# core register map
Vendor: litex
Registers are 32-bit, read-write, reset 0x0 unless marked. A register's access mark holds for its fields unless they carry their own. Offsets are from the block's base; [hi:lo] are bit positions; {n}, {i} and the like mark numbered series.

## COREUSER
Base 0xE0002000
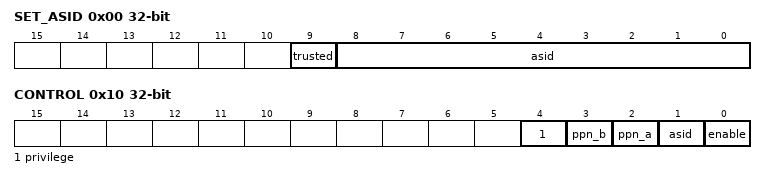
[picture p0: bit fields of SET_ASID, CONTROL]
0x00 SET_ASID
  [9] trusted — Set to `1` if the ASID is trusted
  [8:0] asid — ASID to set. Writing to this register commits the value in `trusted` to the specified `asid` value
0x04 GET_ASID_ADDR
  [8:0] asid — ASID to read back.
0x08 GET_ASID_VALUE
  [0] value — Value corresponding to the ASID specified in `get_asid_addr`. `1` means trusted
0x0C SET_PRIVILEGE
  [1:0] mpp — Value of `mpp` bit from `mstatus` that must match for code to be trusted
0x10 CONTROL
  [4] privilege — When set to `1`, requires the current privilege state to match that specified in `set_privilege.mpp`
  [3] ppn_b — When set to `1`, requires the `b` `ppn` window to be trusted to assert `CoreUser`
  [2] ppn_a — When set to `1`, requires the `a` `ppn` window to be trusted to assert `CoreUser`
  [1] asid — When `1`, requires the ASID mapping to be trusted to assert `CoreUser`
  [0] enable — Enable `CoreUser` computation. When set to `1`, the settings are applied; when cleared to `0`, the `CoreUser` signal is always valid. Defaults to `0`.
0x14 PROTECT — Writing `1` to this bit prevents any further updates to CoreUser configuration status. Can only be reversed with a system reset.
  [0] protect
0x18 WINDOW_AL
  [21:0] ppn — PPN match value, `a` window lower bound. Matches if ppn is greater than or equal to this value
0x1C WINDOW_AH
  [21:0] ppn — PPN match value, `a` window upper bound. Matches if ppn is less than or equal to this value (so a value of 255 would match everything from 0 to 255; resulting in 256 total locations
0x20 WINDOW_BL
  [21:0] ppn — PPN match value, `b` window lower bound. Matches if ppn is greater than or equal to this value
0x24 WINDOW_BH
  [21:0] ppn — PPN match value, `b` window upper bound. Matches if ppn is less than or equal to this value (so a value of 255 would match everything from 0 to 255; resulting in 256 total locations

## CSRTEST
Base 0xE0003000
0x00 WTEST — Write test data here
0x04 RTEST — Read test data here

## IRQARRAY0
Base 0xE0004000
Same registers: IRQARRAY1 0xE0005000, IRQARRAY{n} {0xDFFFC000+0x1000*n} (n=10..19), IRQARRAY{n} {0xE000E000+0x1000*n} (n=2..9)
0x00 EV_SOFT — Software interrupt trigger register. Bits set to `1` will trigger an interrupt. Interrupts trigger on write, but the value will persist in the register, allowing software to determine if a software interrupt was triggered by reading back the register. Software is responsible for clearing the register to 0. Repeated `1` writes without clearing will still trigger an interrupt.
  [19:0] trigger
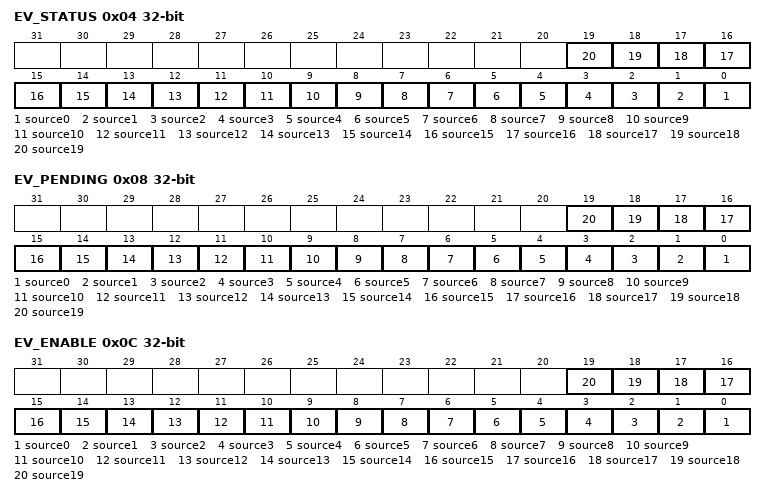
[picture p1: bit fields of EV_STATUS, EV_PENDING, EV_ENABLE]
0x04 EV_STATUS — `1` when a source19 event occurs. This event uses an `EventSourceFlex` form of triggering
  [n] source{n} (n=0..19) — Level of the ``source{n}`` event
0x08 EV_PENDING — `1` when a source19 event occurs. This event uses an `EventSourceFlex` form of triggering
  [n] source{n} (n=0..19) — `1` when a source{n} event occurs. This event uses an `EventSourceFlex` form of triggering
0x0C EV_ENABLE — `1` when a source19 event occurs. This event uses an `EventSourceFlex` form of triggering
  [n] source{n} (n=0..19) — Write a ``1`` to enable the ``source{n}`` Event

## MAILBOX
Base 0xE0018000
0x00 WDATA — Write data to outgoing FIFO.
0x04 RDATA — Read data from incoming FIFO.
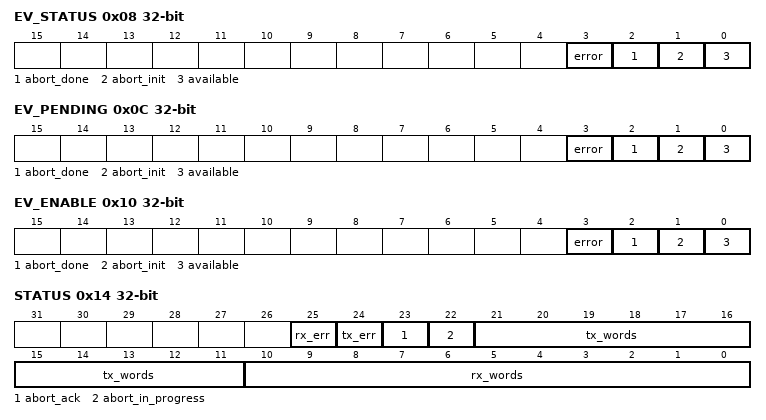
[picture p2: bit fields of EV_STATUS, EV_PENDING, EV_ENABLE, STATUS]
0x08 EV_STATUS — Triggers if either `tx_err` or `rx_err` are asserted
  [3] error — Level of the ``error`` event
  [2] abort_done — Level of the ``abort_done`` event
  [1] abort_init — Level of the ``abort_init`` event
  [0] available — Level of the ``available`` event
0x0C EV_PENDING — Triggers if either `tx_err` or `rx_err` are asserted
  [3] error — Triggers if either `tx_err` or `rx_err` are asserted
  [2] abort_done — Triggers when a previously initiated abort is acknowledged by peer
  [1] abort_init — Triggers when abort is asserted by the peer, and there is currently no abort in progress
  [0] available — Triggers when the `done` signal was asserted by the corresponding peer
0x10 EV_ENABLE — Triggers if either `tx_err` or `rx_err` are asserted
  [3] error — Write a ``1`` to enable the ``error`` Event
  [2] abort_done — Write a ``1`` to enable the ``abort_done`` Event
  [1] abort_init — Write a ``1`` to enable the ``abort_init`` Event
  [0] available — Write a ``1`` to enable the ``available`` Event
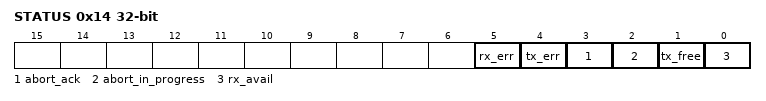
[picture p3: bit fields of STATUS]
0x14 STATUS
  [25] rx_err — Set if read FIFO underflowed because we read too much data. Cleared on register read.
  [24] tx_err — Set if the write FIFO overflowed because we wrote too much data. Cleared on register read.
  [23] abort_ack — This bit is set by the peer that acknowledged the incoming abort (the later of the two, in case of an imperfect race condition). The abort response handler should check this bit; if it is set, no new acknowledgement shall be issued. The bit is cleared when an initiator initiates a new abort. The initiator shall also ignore the state of this bit if it is intending to initiate a new abort cycle.
  [22] abort_in_progress — This bit is set if an `aborting` event was initiated and is still in progress.
  [21:11] tx_words — Number of words pending in write FIFO. Free space is 1024 - `tx_avail`
  [10:0] rx_words — Number of words available to read
0x18 CONTROL
  [0] abort — Write `1` to this field to both initiate and acknowledge an abort. Empties both FIFOs, asserts `aborting`, and prevents an interrupt from being generated by an incoming abort request. New reads & writes are ignored until `aborted` is asserted from the peer.
0x1C DONE
  [0] done — Writing a `1` to this field indicates to the corresponding peer that a full packet is done loading. There is no need to clear this register after writing.

## MB_CLIENT
Base 0xE0019000
Registers as MAILBOX; these are added or differ:
0x14 STATUS
  [5] rx_err — Set if the recipient didn't have data available for a read. Cleared on read.
  [4] tx_err — Set if the recipient was not ready for the data. Cleared on read.
  [3] abort_ack — This bit is set by the peer that acknowledged the incoming abort (the later of the two, in case of an imperfect race condition). The abort response handler should check this bit; if it is set, no new acknowledgement shall be issued. The bit is cleared when an initiator initiates a new abort. The initiator shall also ignore the state of this bit if it is intending to initiate a new abort cycle.
  [2] abort_in_progress — This bit is set if an `aborting` event was initiated and is still in progress.
  [1] tx_free — Tx register can be written
  [0] rx_avail — Rx data is available

## RESETVALUE
Base 0xE001A000
0x00 PC — Latched value for PC on reset

## TICKTIMER
Base 0xE001B000
0x00 CONTROL
  [0] reset — Write a `1` to this bit to reset the count to 0. This bit has priority over all other requests.
0x04 TIME1 — Bits 32-63 of `TICKTIMER_TIME`. Elapsed time in systicks
  [31:0] time
0x08 TIME0 — Bits 0-31 of `TICKTIMER_TIME`.
  [31:0] time
0x0C MSLEEP_TARGET1 — Bits 32-63 of `TICKTIMER_MSLEEP_TARGET`. Target time in 1.0ms ticks
  [31:0] msleep_target
0x10 MSLEEP_TARGET0 — Bits 0-31 of `TICKTIMER_MSLEEP_TARGET`.
  [31:0] msleep_target
0x14 EV_STATUS — This register contains the current raw level of the alarm event trigger. Writes to this register have no effect.
  [0] alarm — Level of the ``alarm`` event
0x18 EV_PENDING — When a alarm event occurs, the corresponding bit will be set in this register. To clear the Event, set the corresponding bit in this register.
  [0] alarm — `1` if a `alarm` event occurred. This Event is **level triggered** when the signal is **high**.
0x1C EV_ENABLE — This register enables the corresponding alarm events. Write a ``0`` to this register to disable individual events.
  [0] alarm — Write a ``1`` to enable the ``alarm`` Event
0x20 CLOCKS_PER_TICK reset 0xC3500 — Clocks per tick, defaults to 800000
